# S32K148_M4 register map
Vendor: NXP Semiconductors; File version: 1.1a
CPU: CM4 r0p1, little endian, MPU, FPU, VTOR, 4 interrupt priority bits
Registers are 32-bit, read-write, reset 0x0 unless marked. A register's access mark holds for its fields unless they carry their own. Offsets are from the block's base; [hi:lo] are bit positions; {n}, {i} and the like mark numbered series; 'fields as' and 'values as' point back to an identical list.

## ADC0 — ADC
Base 0x4003B000
Same registers: ADC1 0x40027000
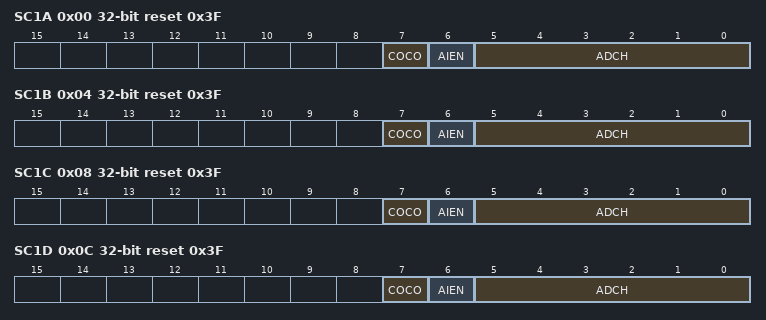
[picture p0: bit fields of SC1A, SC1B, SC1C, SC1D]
0x00 SC1A reset 0x3F — ADC Status and Control Register 1
  [7] COCO ro — Conversion Complete Flag
    0=Conversion is not completed; 1=Conversion is completed
  [6] AIEN — Interrupt Enable
    0=Conversion complete interrupt is disabled; 1=Conversion complete interrupt is enabled
  [5:0] ADCH — Input channel select
    {v}=External channel {v} is selected as input (v=0..15); 21=Internal channel 0 is selected as input; 22=Internal channel 1 is selected as input; 23=Internal channel 2 is selected as input; 27=Band Gap; 28=Internal channel 3 is selected as input; 29=VREFSH is selected as input. Voltage reference selected is determined by SC2[REFSEL].; 30=VREFSL is selected as input. Voltage reference selected is determined by SC2[REFSEL].; {v}=External channel {v-16} is selected as input (v=32..47); 63=Module is disabled
0x04 SC1B reset 0x3F — ADC Status and Control Register 1
  fields as SC1A
0x08 SC1C reset 0x3F — ADC Status and Control Register 1
  fields as SC1A
0x0C SC1D reset 0x3F — ADC Status and Control Register 1
  fields as SC1A
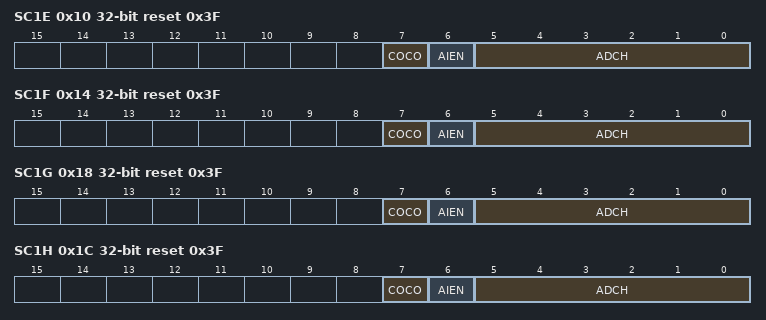
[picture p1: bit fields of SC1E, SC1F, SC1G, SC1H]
0x10 SC1E reset 0x3F — ADC Status and Control Register 1
  fields as SC1A
0x14 SC1F reset 0x3F — ADC Status and Control Register 1
  fields as SC1A
0x18 SC1G reset 0x3F — ADC Status and Control Register 1
  fields as SC1A
0x1C SC1H reset 0x3F — ADC Status and Control Register 1
  fields as SC1A
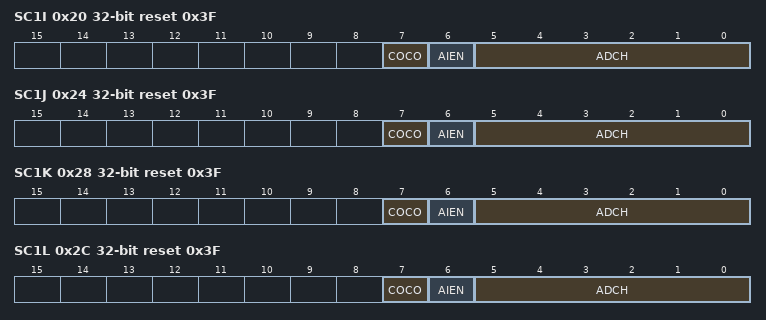
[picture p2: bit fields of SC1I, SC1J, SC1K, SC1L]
0x20 SC1I reset 0x3F — ADC Status and Control Register 1
  fields as SC1A
0x24 SC1J reset 0x3F — ADC Status and Control Register 1
  fields as SC1A
0x28 SC1K reset 0x3F — ADC Status and Control Register 1
  fields as SC1A
0x2C SC1L reset 0x3F — ADC Status and Control Register 1
  fields as SC1A
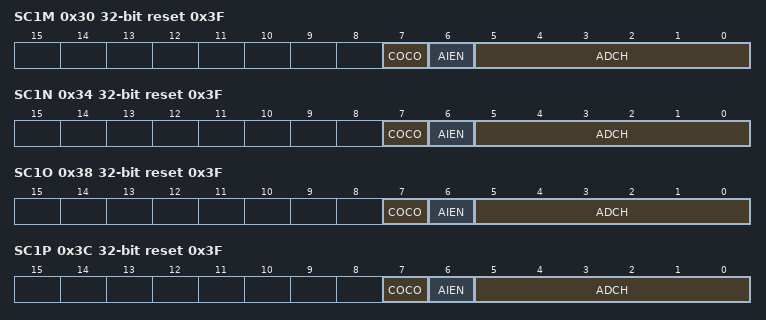
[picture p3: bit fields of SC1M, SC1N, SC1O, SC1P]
0x30 SC1M reset 0x3F — ADC Status and Control Register 1
  fields as SC1A
0x34 SC1N reset 0x3F — ADC Status and Control Register 1
  fields as SC1A
0x38 SC1O reset 0x3F — ADC Status and Control Register 1
  fields as SC1A
0x3C SC1P reset 0x3F — ADC Status and Control Register 1
  fields as SC1A
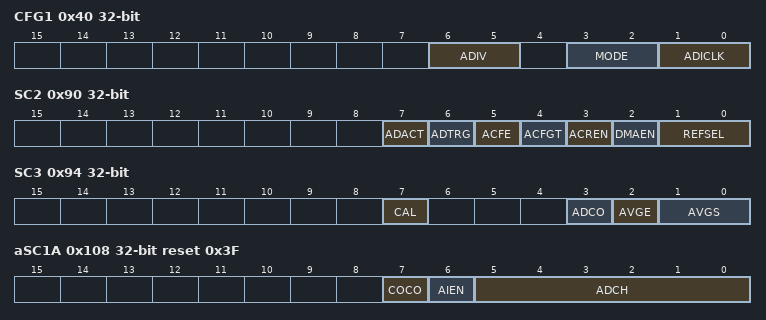
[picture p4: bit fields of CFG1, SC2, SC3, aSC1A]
0x40 CFG1 — ADC Configuration Register 1
  [6:5] ADIV — Clock Divide Select
    0=The divide ratio is 1 and the clock rate is input clock; 1=The divide ratio is 2 and the clock rate is (input clock)/2; 2=The divide ratio is 4 and the clock rate is (input clock)/4; 3=The divide ratio is 8 and the clock rate is (input clock)/8
  [3:2] MODE — Conversion mode selection
    0=8-bit conversion; 1=12-bit conversion; 2=10-bit conversion
  [1:0] ADICLK — Input Clock Select
    {v}=Alternate clock {v+1} (ALTCLK{v+1}) (v=0..3)
0x44 CFG2 reset 0xC — ADC Configuration Register 2
  [7:0] SMPLTS — Sample Time Select
0x48 RA ro — ADC Data Result Registers
  [11:0] D — Data result
0x4C RB ro — ADC Data Result Registers
  [11:0] D — Data result
0x50 RC ro — ADC Data Result Registers
  [11:0] D — Data result
0x54 RD ro — ADC Data Result Registers
  [11:0] D — Data result
0x58 RE ro — ADC Data Result Registers
  [11:0] D — Data result
0x5C RF ro — ADC Data Result Registers
  [11:0] D — Data result
0x60 RG ro — ADC Data Result Registers
  [11:0] D — Data result
0x64 RH ro — ADC Data Result Registers
  [11:0] D — Data result
0x68 RI ro — ADC Data Result Registers
  [11:0] D — Data result
0x6C RJ ro — ADC Data Result Registers
  [11:0] D — Data result
0x70 RK ro — ADC Data Result Registers
  [11:0] D — Data result
0x74 RL ro — ADC Data Result Registers
  [11:0] D — Data result
0x78 RM ro — ADC Data Result Registers
  [11:0] D — Data result
0x7C RN ro — ADC Data Result Registers
  [11:0] D — Data result
0x80 RO ro — ADC Data Result Registers
  [11:0] D — Data result
0x84 RP ro — ADC Data Result Registers
  [11:0] D — Data result
{0x84+4i} CV{i} (i=1..2) — Compare Value Registers
  [15:0] CV — Compare Value.
0x90 SC2 — Status and Control Register 2
  [7] ADACT ro — Conversion Active
    0=Conversion not in progress; 1=Conversion in progress
  [6] ADTRG — Conversion Trigger Select
    0=Software trigger selected; 1=Hardware trigger selected
  [5] ACFE — Compare Function Enable
    0=Compare function disabled; 1=Compare function enabled
  [4] ACFGT — Compare Function Greater Than Enable
  [3] ACREN — Compare Function Range Enable
  [2] DMAEN — DMA Enable
    0=DMA is disabled; 1=DMA is enabled and will assert the ADC DMA request during an ADC conversion complete event , which is indicated when any SC1n[COCO] flag is asserted
  [1:0] REFSEL — Voltage Reference Selection
    0=Default voltage reference pin pair, that is, external pins VREFH and VREFL; 1=Alternate reference voltage, that is, VALTH. This voltage may be additional external pin or internal source depending on the MCU configuration. See the chip configuration information for details specific to this MCU.
0x94 SC3 — Status and Control Register 3
  [7] CAL — Calibration
  [3] ADCO — Continuous Conversion Enable
    0=One conversion will be performed (or one set of conversions, if AVGE is set) after a conversion is initiated; 1=Continuous conversions will be performed (or continuous sets of conversions, if AVGE is set) after a conversion is initiated
  [2] AVGE — Hardware Average Enable
    0=Hardware average function disabled; 1=Hardware average function enabled
  [1:0] AVGS — Hardware Average Select
    0=4 samples averaged; 1=8 samples averaged; 2=16 samples averaged; 3=32 samples averaged
0x98 BASE_OFS reset 0x40 — BASE Offset Register
  [7:0] BA_OFS — Base Offset Error Correction Value
0x9C OFS (reset mask 0xFFFF0000) — ADC Offset Correction Register
  [15:0] OFS — Offset Error Correction Value
0xA0 USR_OFS — USER Offset Correction Register
  [7:0] USR_OFS — USER Offset Error Correction Value
0xA4 XOFS reset 0x30 — ADC X Offset Correction Register
  [5:0] XOFS — X offset error correction value
0xA8 YOFS reset 0x37 — ADC Y Offset Correction Register
  [7:0] YOFS — Y offset error correction value
0xAC G (reset mask 0xFFFFF800) — ADC Gain Register
  [10:0] G
0xB0 UG reset 0x4 — ADC User Gain Register
  [9:0] UG
0xB4 CLPS (reset mask 0xFFFFFF80) — ADC General Calibration Value Register S
  [6:0] CLPS
0xB8 CLP3 (reset mask 0xFFFFFC00) — ADC Plus-Side General Calibration Value Register 3
  [9:0] CLP3
0xBC CLP2 (reset mask 0xFFFFFC00) — ADC Plus-Side General Calibration Value Register 2
  [9:0] CLP2
0xC0 CLP1 (reset mask 0xFFFFFE00) — ADC Plus-Side General Calibration Value Register 1
  [8:0] CLP1
0xC4 CLP0 (reset mask 0xFFFFFF00) — ADC Plus-Side General Calibration Value Register 0
  [7:0] CLP0
0xC8 CLPX (reset mask 0xFFFFFF80) — ADC Plus-Side General Calibration Value Register X
  [6:0] CLPX
0xCC CLP9 (reset mask 0xFFFFFF80) — ADC Plus-Side General Calibration Value Register 9
  [6:0] CLP9
0xD0 CLPS_OFS — ADC General Calibration Offset Value Register S
  [3:0] CLPS_OFS — CLPS Offset
0xD4 CLP3_OFS — ADC Plus-Side General Calibration Offset Value Register 3
  [3:0] CLP3_OFS — CLP3 Offset
0xD8 CLP2_OFS — ADC Plus-Side General Calibration Offset Value Register 2
  [3:0] CLP2_OFS — CLP2 Offset
0xDC CLP1_OFS — ADC Plus-Side General Calibration Offset Value Register 1
  [3:0] CLP1_OFS — CLP1 Offset
0xE0 CLP0_OFS — ADC Plus-Side General Calibration Offset Value Register 0
  [3:0] CLP0_OFS — CLP0 Offset
0xE4 CLPX_OFS reset 0x440 — ADC Plus-Side General Calibration Offset Value Register X
  [11:0] CLPX_OFS — CLPX Offset
0xE8 CLP9_OFS reset 0x240 — ADC Plus-Side General Calibration Offset Value Register 9
  [11:0] CLP9_OFS — CLP9 Offset
0x108 aSC1A reset 0x3F — ADC Status and Control Register 1
  fields as SC1A
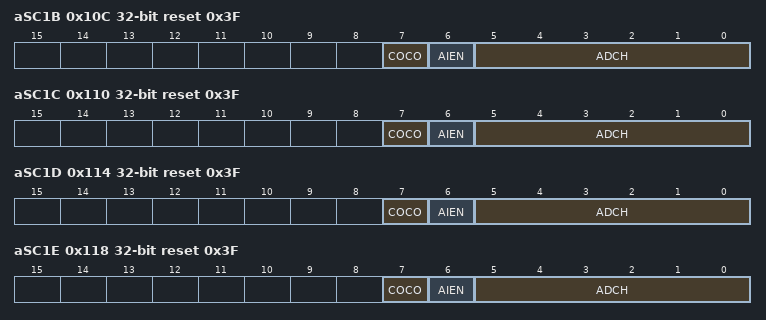
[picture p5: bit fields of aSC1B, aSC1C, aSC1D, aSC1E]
0x10C aSC1B reset 0x3F — ADC Status and Control Register 1
  fields as SC1A
0x110 aSC1C reset 0x3F — ADC Status and Control Register 1
  fields as SC1A
0x114 aSC1D reset 0x3F — ADC Status and Control Register 1
  fields as SC1A
0x118 aSC1E reset 0x3F — ADC Status and Control Register 1
  fields as SC1A
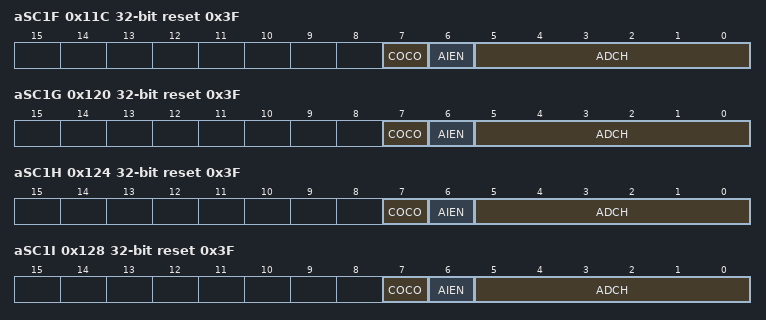
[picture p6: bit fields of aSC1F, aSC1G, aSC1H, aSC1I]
0x11C aSC1F reset 0x3F — ADC Status and Control Register 1
  fields as SC1A
0x120 aSC1G reset 0x3F — ADC Status and Control Register 1
  fields as SC1A
0x124 aSC1H reset 0x3F — ADC Status and Control Register 1
  fields as SC1A
0x128 aSC1I reset 0x3F — ADC Status and Control Register 1
  fields as SC1A
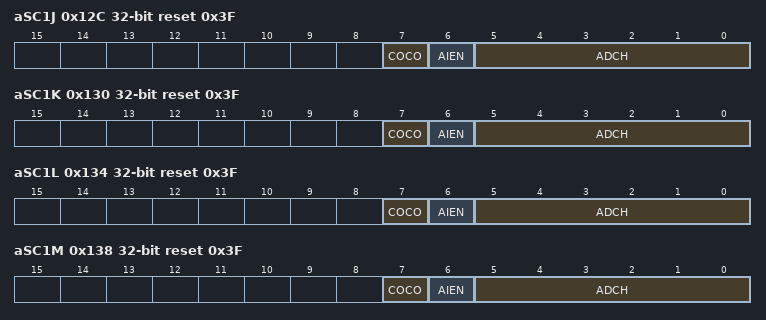
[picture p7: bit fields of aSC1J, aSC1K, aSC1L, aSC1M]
0x12C aSC1J reset 0x3F — ADC Status and Control Register 1
  fields as SC1A
0x130 aSC1K reset 0x3F — ADC Status and Control Register 1
  fields as SC1A
0x134 aSC1L reset 0x3F — ADC Status and Control Register 1
  fields as SC1A
0x138 aSC1M reset 0x3F — ADC Status and Control Register 1
  fields as SC1A
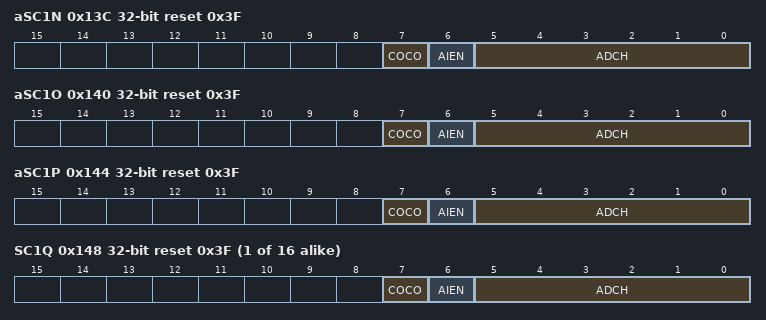
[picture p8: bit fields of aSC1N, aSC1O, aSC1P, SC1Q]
0x13C aSC1N reset 0x3F — ADC Status and Control Register 1
  fields as SC1A
0x140 aSC1O reset 0x3F — ADC Status and Control Register 1
  fields as SC1A
0x144 aSC1P reset 0x3F — ADC Status and Control Register 1
  fields as SC1A
0x148 SC1{x} (x=Q,R,S,T,U,V,W,X,Y,Z,AA,AB,AC,AD,AE,AF; step 0x4) reset 0x3F — ADC Status and Control Register 1
  fields as SC1A
0x188 aRA ro — ADC Data Result Registers
  [11:0] D — Data result
0x18C aRB ro — ADC Data Result Registers
  [11:0] D — Data result
0x190 aRC ro — ADC Data Result Registers
  [11:0] D — Data result
0x194 aRD ro — ADC Data Result Registers
  [11:0] D — Data result
0x198 aRE ro — ADC Data Result Registers
  [11:0] D — Data result
0x19C aRF ro — ADC Data Result Registers
  [11:0] D — Data result
0x1A0 aRG ro — ADC Data Result Registers
  [11:0] D — Data result
0x1A4 aRH ro — ADC Data Result Registers
  [11:0] D — Data result
0x1A8 aRI ro — ADC Data Result Registers
  [11:0] D — Data result
0x1AC aRJ ro — ADC Data Result Registers
  [11:0] D — Data result
0x1B0 aRK ro — ADC Data Result Registers
  [11:0] D — Data result
0x1B4 aRL ro — ADC Data Result Registers
  [11:0] D — Data result
0x1B8 aRM ro — ADC Data Result Registers
  [11:0] D — Data result
0x1BC aRN ro — ADC Data Result Registers
  [11:0] D — Data result
0x1C0 aRO ro — ADC Data Result Registers
  [11:0] D — Data result
0x1C4 aRP ro — ADC Data Result Registers
  [11:0] D — Data result
0x1C8 R{x} (x=Q,R,S,T,U,V,W,X,Y,Z,AA,AB,AC,AD,AE,AF; step 0x4) ro — ADC Data Result Registers
  [11:0] D — Data result
